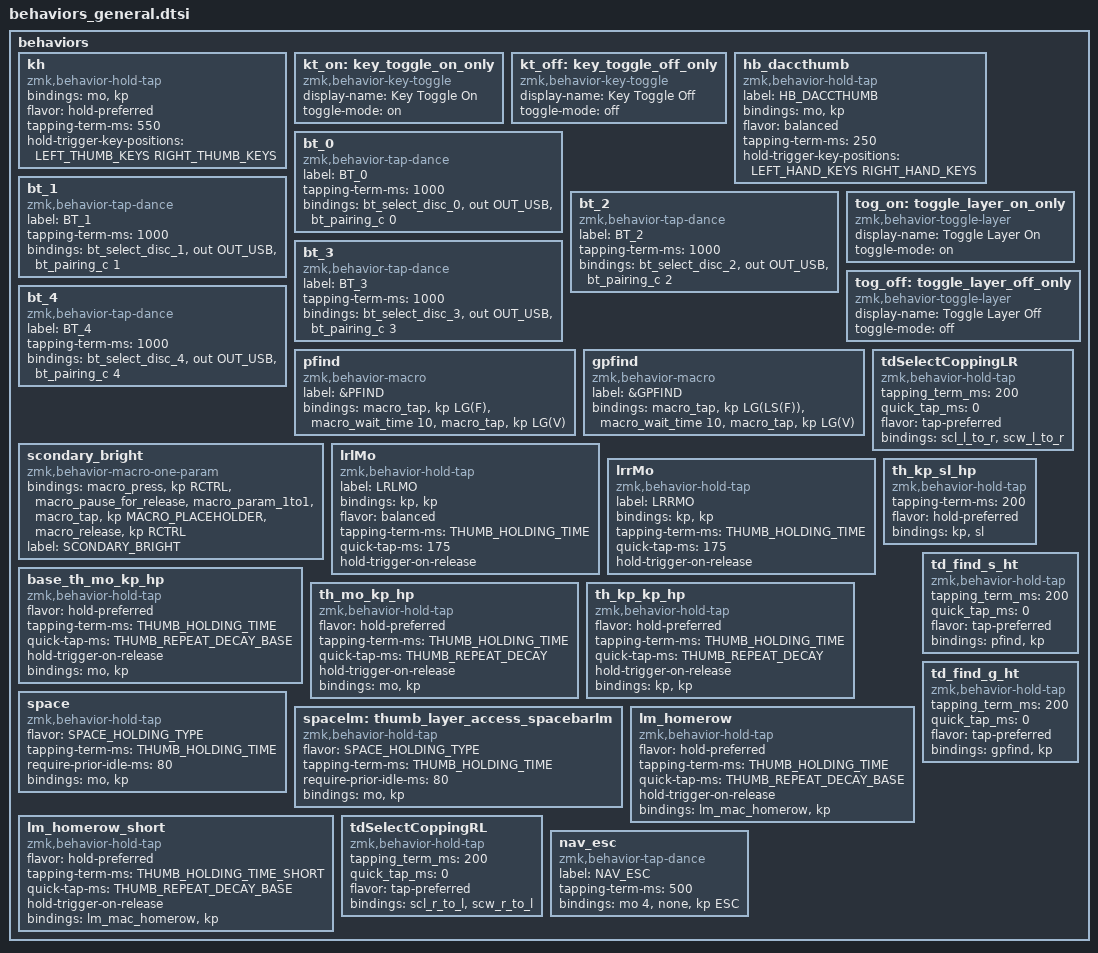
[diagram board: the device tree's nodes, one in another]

#define THUMB_HOLDING_TIME 220 // THUMB_HOLDING_TIME defines how long you need to hold (milliseconds) a thumb key to activate a layer.  Shorter holds are treated as taps.
#define THUMB_HOLDING_TIME_SHORT 150
#define THUMB_REPEAT_DECAY_BASE 0 // "tap then hold" for key auto-repeat
#define THUMB_REPEAT_DECAY 190 // "tap then hold" for key auto-repeat
#define SPACE_HOLDING_TYPE "balanced"

#define LEFT_HAND_KEYS          \
                             0  1  2  3  4  \
                            10 11 12 13 14  \ 
                        20  21 22 23 24 25   


#define RIGHT_HAND_KEYS          \
                                          5  6  7  8  9 \
                                         15 16 17 18 19 \
                                      26 27 28 29 30 31


#define LEFT_THUMB_KEYS          \
                        32 33 34         

#define RIGHT_THUMB_KEYS          \
                        35 36 37 

   
    behaviors {
        kh: kh {
            compatible = "zmk,behavior-hold-tap";
            bindings = <&mo>, <&kp>;
            #binding-cells = <2>;
            flavor = "hold-preferred";
            tapping-term-ms = <550>;
            hold-trigger-key-positions = < LEFT_THUMB_KEYS RIGHT_THUMB_KEYS >;
        };

        kt_on: key_toggle_on_only {
            compatible = "zmk,behavior-key-toggle";
            #binding-cells = <1>;
            display-name = "Key Toggle On";
            toggle-mode = "on";
        };

        kt_off: key_toggle_off_only {
            compatible = "zmk,behavior-key-toggle";
            #binding-cells = <1>;
            display-name = "Key Toggle Off";
            toggle-mode = "off";
        };

        hb_daccthumb: hb_daccthumb {
            compatible = "zmk,behavior-hold-tap";
            label = "HB_DACCTHUMB";
            bindings = <&mo >, <&kp>;
            #binding-cells = <2>;
            flavor = "balanced";
            tapping-term-ms = <250>;
            hold-trigger-key-positions = < LEFT_HAND_KEYS RIGHT_HAND_KEYS >;
        };

        bt_0: bt_0 {
            compatible = "zmk,behavior-tap-dance";
            label = "BT_0";
            #binding-cells = <0>;
            tapping-term-ms = <1000>;
            bindings = <&bt_select_disc_0>, <&out OUT_USB>, <&bt_pairing_c 0>;
        };

        bt_1: bt_1 {
            compatible = "zmk,behavior-tap-dance";
            label = "BT_1";
            #binding-cells = <0>;
            tapping-term-ms = <1000>;
            bindings = <&bt_select_disc_1>, <&out OUT_USB>, <&bt_pairing_c 1>;
        };

        bt_2: bt_2 {
            compatible = "zmk,behavior-tap-dance";
            label = "BT_2";
            #binding-cells = <0>;
            tapping-term-ms = <1000>;
            bindings = <&bt_select_disc_2>, <&out OUT_USB>, <&bt_pairing_c 2>;
        };

        bt_3: bt_3 {
            compatible = "zmk,behavior-tap-dance";
            label = "BT_3";
            #binding-cells = <0>;
            tapping-term-ms = <1000>;
            bindings = <&bt_select_disc_3>, <&out OUT_USB>, <&bt_pairing_c 3>;
        };

        bt_4: bt_4 {
            compatible = "zmk,behavior-tap-dance";
            label = "BT_4";
            #binding-cells = <0>;
            tapping-term-ms = <1000>;
            bindings = <&bt_select_disc_4>, <&out OUT_USB>, <&bt_pairing_c 4>;
        };

        tog_on: toggle_layer_on_only {
            compatible = "zmk,behavior-toggle-layer";
            #binding-cells = <1>;
            display-name = "Toggle Layer On";
            toggle-mode = "on";
        };

        tog_off: toggle_layer_off_only {
            compatible = "zmk,behavior-toggle-layer";
            #binding-cells = <1>;
            display-name = "Toggle Layer Off";
            toggle-mode = "off";
        };

        //  Copy Find

        pfind: pfind {
            label = "&PFIND";
            compatible = "zmk,behavior-macro";
            #binding-cells = <0>;
            bindings =
                <&macro_tap>,
                <&kp LG(F)>,
                <&macro_wait_time 10>,
                <&macro_tap>,
                <&kp LG(V)>;
        };

        // Global Find Paste

        gpfind: gpfind {
            label = "&GPFIND";
            compatible = "zmk,behavior-macro";
            #binding-cells = <0>;
            bindings =
                <&macro_tap>,
                <&kp LG(LS(F))>,
                <&macro_wait_time 10>,
                <&macro_tap>,
                <&kp LG(V)>;
        };

        scondary_bright: scondary_bright {
            compatible = "zmk,behavior-macro-one-param";
            #binding-cells = <1>;
            bindings =
                <&macro_press>,
                <&kp RCTRL>,
                <&macro_pause_for_release>,
                <&macro_param_1to1>,
                <&macro_tap>,
                <&kp MACRO_PLACEHOLDER>,
                <&macro_release>,
                <&kp RCTRL>;

            label = "SCONDARY_BRIGHT";
        };

        tdSelectCoppingLR: tdSelectCoppingLR {
            compatible = "zmk,behavior-hold-tap";
            #binding-cells = <2>;
            tapping_term_ms = <200>;
            quick_tap_ms = <0>;
            flavor = "tap-preferred";
            bindings = <&scl_l_to_r>, <&scw_l_to_r>;
        };

        lrlMo: lrlMo {
            compatible = "zmk,behavior-hold-tap";
            label = "LRLMO";
            bindings = <&kp>, <&kp>;

            #binding-cells = <2>;
            flavor = "balanced";
            tapping-term-ms = <THUMB_HOLDING_TIME>;
            quick-tap-ms = <175>;
            hold-trigger-on-release;
        };

        lrrMo: lrrMo {
            compatible = "zmk,behavior-hold-tap";
            label = "LRRMO";
            bindings = <&kp>, <&kp>;

            #binding-cells = <2>;
            tapping-term-ms = <THUMB_HOLDING_TIME>;
            quick-tap-ms = <175>;
            hold-trigger-on-release;
        };

        base_th_mo_kp_hp: base_th_mo_kp_hp {
            compatible = "zmk,behavior-hold-tap";
            flavor = "hold-preferred";
            tapping-term-ms = <THUMB_HOLDING_TIME>;
            quick-tap-ms = <THUMB_REPEAT_DECAY_BASE>; // enable repeat
            hold-trigger-on-release; // wait for other home row mods
            #binding-cells = <2>;
            bindings = <&mo>, <&kp>;
        };

        th_mo_kp_hp: th_mo_kp_hp {
            compatible = "zmk,behavior-hold-tap";
            flavor = "hold-preferred";
            tapping-term-ms = <THUMB_HOLDING_TIME>;
            quick-tap-ms = <THUMB_REPEAT_DECAY>; // enable repeat
            hold-trigger-on-release; // wait for other home row mods
            #binding-cells = <2>;
            bindings = <&mo>, <&kp>;
        };

        th_kp_kp_hp: th_kp_kp_hp {
            compatible = "zmk,behavior-hold-tap";
            flavor = "hold-preferred";
            tapping-term-ms = <THUMB_HOLDING_TIME>;
            quick-tap-ms = <THUMB_REPEAT_DECAY>; // enable repeat
            #binding-cells = <2>;
            hold-trigger-on-release;
            bindings = <&kp>, <&kp>;
        };

        space: space {
            compatible = "zmk,behavior-hold-tap";
            flavor =
            SPACE_HOLDING_TYPE;
            tapping-term-ms = <THUMB_HOLDING_TIME>;
            //quick-tap-ms = <THUMB_REPEAT_DECAY>; // enable repeat
            #binding-cells = <2>;
            require-prior-idle-ms = <80>;
            bindings = <&mo>, <&kp>;
        };

        spacelm: thumb_layer_access_spacebarlm {
            compatible = "zmk,behavior-hold-tap";
            flavor =
            SPACE_HOLDING_TYPE;
            tapping-term-ms = <THUMB_HOLDING_TIME>;
            //quick-tap-ms = <THUMB_REPEAT_DECAY_BASE>; // enable repeat
            #binding-cells = <2>;
            require-prior-idle-ms = <80>;
            bindings = <&mo>, <&kp>;
        };

        th_kp_sl_hp: th_kp_sl_hp {
            compatible = "zmk,behavior-hold-tap";
            #binding-cells = <2>;
            tapping-term-ms = <200>;    // <---[[moderate duration]]
            flavor = "hold-preferred";
            bindings = <&kp>, <&sl>;
        };

        lm_homerow: lm_homerow {
            compatible = "zmk,behavior-hold-tap";
            flavor = "hold-preferred";
            tapping-term-ms = <THUMB_HOLDING_TIME>;
            quick-tap-ms = <THUMB_REPEAT_DECAY_BASE>; // enable repeat
            hold-trigger-on-release; // wait for other home row mods
            #binding-cells = <2>;
            bindings = <&lm_mac_homerow>, <&kp>;
        };

        lm_homerow_short: lm_homerow_short {
            compatible = "zmk,behavior-hold-tap";
            flavor = "hold-preferred";
            tapping-term-ms = <THUMB_HOLDING_TIME_SHORT>;
            quick-tap-ms = <THUMB_REPEAT_DECAY_BASE>; // enable repeat
            hold-trigger-on-release; // wait for other home row mods
            #binding-cells = <2>;
            bindings = <&lm_mac_homerow>, <&kp>;
        };

        tdSelectCoppingRL: tdSelectCoppingRL {
            compatible = "zmk,behavior-hold-tap";
            #binding-cells = <2>;
            tapping_term_ms = <200>;
            quick_tap_ms = <0>;
            flavor = "tap-preferred";
            bindings = <&scl_r_to_l>, <&scw_r_to_l>;
        };

        td_find_s_ht: td_find_s_ht {
            compatible = "zmk,behavior-hold-tap";
            #binding-cells = <2>;
            tapping_term_ms = <200>;
            quick_tap_ms = <0>;
            flavor = "tap-preferred";
            bindings = <&pfind>, <&kp>;
        };

        td_find_g_ht: td_find_g_ht {
            compatible = "zmk,behavior-hold-tap";
            #binding-cells = <2>;
            tapping_term_ms = <200>;
            quick_tap_ms = <0>;
            flavor = "tap-preferred";
            bindings = <&gpfind>, <&kp>;
        };

        nav_esc: nav_esc {
            compatible = "zmk,behavior-tap-dance";
            label = "NAV_ESC";
            #binding-cells = <0>;
            tapping-term-ms = <500>;
            bindings = <&mo 4>, <&none>, <&kp ESC>;
        };
/*
        td_nav_esc: td_nav_esc {
            compatible = "zmk,behavior-tap-dance";
            label = "TD_NAV_ESC";
            #binding-cells = <0>;
            tapping-term-ms = <500>;
            bindings = <&td_nav_num NAVOVERR NUMBERS>, <&kp ESC>;
        };

        td_nav_num: td_nav_num {
            compatible = "zmk,behavior-hold-tap";
            #binding-cells = <2>;
            tapping_term_ms = <200>;
            quick_tap_ms = <0>;
            flavor = "tap-preferred";
            bindings = <&mo>, <&tog_on>;
        };
        */
    };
